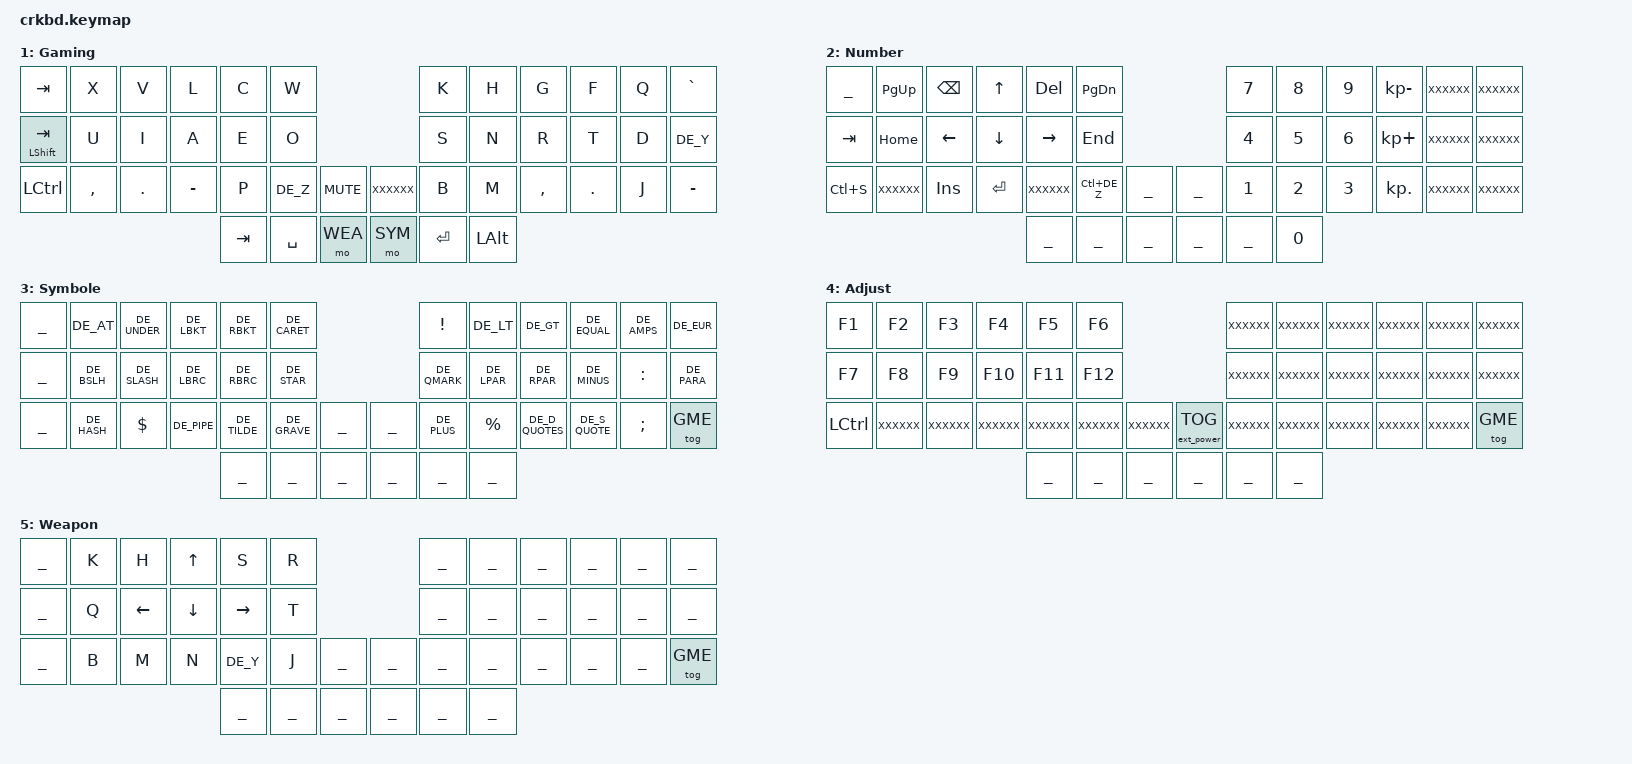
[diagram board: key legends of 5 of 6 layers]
 /*
 * Copyright (c) 2020 The ZMK Contributors
 *
 * SPDX-License-Identifier: MIT
 * NEO 2
 */


#include <behaviors.dtsi>
#include <dt-bindings/zmk/keys.h>
#include <dt-bindings/zmk/bt.h>
#include <dt-bindings/zmk/modifiers.h>
#include <dt-bindings/zmk/ext_power.h>
#include "define_keys.dtsi"
#include "taps.keymap"

#define WIN 0
#define GME 1
#define NUM 2
#define SYM 3
#define ADJ 4
#define WEA 5 


/ {

   // Activate ADJUST layer by pressing raise and lower
    conditional_layers {
        compatible = "zmk,conditional-layers";
        adjust_layer {
            if-layers = <SYM NUM>;
            then-layer = <ADJ>;
        };
    };

    keymap {
        compatible = "zmk,keymap";
        win_layer {
            label = "Windows";
            bindings = < RC(LA(R))
// ╭────────────────┬────────────────┬────────────────┬────────────────┬────────────────┬────────────────╮                                   ╭────────────────┬────────────────┬────────────────┬────────────────┬────────────────┬────────────────╮
        &kp ESC           &kp X            &kp V          &bhm F2 C       &bhm RC(D) C     &bhm RC(U) W                                            &kp K            &kp H            &kp G            &kp F            &kp Q           &kp DE_SS
// ├────────────────┼────────────────┼────────────────┼────────────────┼────────────────┼────────────────┤                                   ├────────────────┼────────────────┼────────────────┼────────────────┼────────────────┼────────────────┤
     &mt LSHIFT TAB  &bhm RC(LA(P)) U &bhm RC(LA(R)) I    &bhm F12 A      &bhm LS(F5) E     &bhm F5 O                                              &kp S            &kp N            &kp R            &kp T            &kp D           &kp DE_Y
// ├────────────────┼────────────────┼────────────────┼────────────────┼────────────────┼────────────────┤                                   ├────────────────┼────────────────┼────────────────┼────────────────┼────────────────┤────────────────┤
        &kp LCTRL       &kp DE_UE        &kp DE_OE        &kp DE_AE          &kp P           &kp DE_Z                                              &kp B            &kp M           &kp COMMA        &kp DOT           &kp J         &kp DE_MINUS
// ╰────────────────┴────────────────┴────────────────┴────────────────┼────────────────┼────────────────┤────────────────╮ ╭────────────────┼────────────────┼────────────────┼────────────────┴────────────────┴────────────────┴────────────────╯
                                                                         &mt LALT LGUI      &kp SPACE        &mo NUM             &mo SYM      &mt RSHIFT RET      &kp RALT       
//                                                                     ╰────────────────┴────────────────┴────────────────╯ ╰────────────────┴────────────────┴────────────────╯
            >;
            sensor-bindings = <&inc_dec_kp C_VOL_UP C_VOL_DN &inc_dec_kp PG_UP PG_DN>;
        };
// -------------------------------------------------------------------------------------------------------------------------------------------------------------------------------------------------------------------------------------------------
        gme_layer {
            label = "Gaming";
            bindings = <
// ╭────────────────┬────────────────┬────────────────┬────────────────┬────────────────┬────────────────╮                                   ╭────────────────┬────────────────┬────────────────┬────────────────┬────────────────┬────────────────╮
         &kp TAB          &kp X            &kp V             &kp L           &kp C            &kp W                                                &kp K            &kp H            &kp G             &kp F            &kp Q          &kp GRAVE
// ├────────────────┼────────────────┼────────────────┼────────────────┼────────────────┼────────────────┤                                   ├────────────────┼────────────────┼────────────────┼────────────────┼────────────────┼────────────────┤
     &mt LSHIFT TAB       &kp U            &kp I             &kp A           &kp E            &kp O                                                &kp S            &kp N            &kp R             &kp T            &kp D          &kp DE_Y
// ├────────────────┼────────────────┼────────────────┼────────────────┼────────────────┼────────────────┤────────────────╮ ╭────────────────┼────────────────┼────────────────┼────────────────┼────────────────┼────────────────┼────────────────┤
       &kp LCTRL        &kp COMMA         &kp DOT          &kp MINUS         &kp P           &kp DE_Z        &kp C_MUTE           XXXXXX           &kp B            &kp M           &kp COMMA         &kp DOT           &kp J          &kp MINUS
// ╰────────────────┴────────────────┴────────────────┴────────────────┼────────────────┼────────────────┤────────────────┤ ├────────────────┼────────────────┼────────────────┼────────────────┴────────────────┴────────────────┴────────────────╯
                                                                            &kp TAB          &kp SPACE         &mo WEA            &mo SYM          &kp RET         &kp LALT
//                                                                     ╰────────────────┴────────────────┴────────────────╯ ╰────────────────┴────────────────┴────────────────╯
            >;
            sensor-bindings = <&inc_dec_kp C_VOL_UP C_VOL_DN &inc_dec_kp PG_UP PG_DN>;
        };
// -------------------------------------------------------------------------------------------------------------------------------------------------------------------------------------------------------------------------------------------------
        num_layer {
            label = "Number";
            bindings = <

// ╭────────────────┬────────────────┬────────────────┬────────────────┬────────────────┬────────────────╮                                   ╭────────────────┬────────────────┬────────────────┬────────────────┬────────────────┬────────────────╮
         ______         &kp PAGE_UP       &kp BSPC           &kp UP          &kp DEL       &kp PAGE_DOWN                                          &kp N7            &kp N8           &kp N9        &kp KP_MINUS        XXXXXX           XXXXXX
// ├────────────────┼────────────────┼────────────────┼────────────────┼────────────────┼────────────────┤                                   ├────────────────┼────────────────┼────────────────┼────────────────┼────────────────┼────────────────┤
         &kp TAB         &kp HOME         &kp LEFT         &kp DOWN         &kp RIGHT        &kp END                                              &kp N4            &kp N5           &kp N6        &kp KP_PLUS         XXXXXX           XXXXXX
// ├────────────────┼────────────────┼────────────────┼────────────────┼────────────────┼────────────────┤────────────────╮ ╭────────────────┼────────────────┼────────────────┼────────────────┼────────────────┼────────────────┼────────────────┤
         &kp LC(S)        XXXXXX          &kp INS          &kp RET           XXXXXX         &kp LC(DE_Z)       ______             ______          &kp N1            &kp N2           &kp N3         &kp KP_DOT         XXXXXX           XXXXXX
// ╰────────────────┴────────────────┴────────────────┴────────────────┼────────────────┼────────────────┤────────────────┤ ├────────────────┼────────────────┼────────────────┼────────────────┴────────────────┴────────────────┴────────────────╯
                                                                             ______           ______           ______             ______           ______           &kp N0
//                                                                     ╰────────────────┴────────────────┴────────────────╯ ╰────────────────┴────────────────┴────────────────╯
            >;
            sensor-bindings = <&inc_dec_kp C_VOL_UP C_VOL_DN &inc_dec_kp PG_UP PG_DN>;
        };
// -------------------------------------------------------------------------------------------------------------------------------------------------------------------------------------------------------------------------------------------------
        sym_layer {
            label = "Symbole";
            bindings = <
// ╭────────────────┬────────────────┬────────────────┬────────────────┬────────────────┬────────────────╮                                   ╭────────────────┬────────────────┬────────────────┬────────────────┬────────────────┬────────────────╮
         ______          &kp DE_AT       &kp DE_UNDER     &kp DE_LBKT      &kp DE_RBKT     &kp DE_CARET                                            &kp EXCL        &kp DE_LT        &kp DE_GT       &kp DE_EQUAL     &kp DE_AMPS      &kp DE_EUR
// ├────────────────┼────────────────┼────────────────┼────────────────┼────────────────┼────────────────┤                                   ├────────────────┼────────────────┼────────────────┼────────────────┼────────────────┼────────────────┤
         ______         &kp DE_BSLH     &kp DE_SLASH      &kp DE_LBRC      &kp DE_RBRC     &kp DE_STAR                                          &kp DE_QMARK      &kp DE_LPAR      &kp DE_RPAR      &kp DE_MINUS     &kp COLON        &kp DE_PARA
// ├────────────────┼────────────────┼────────────────┼────────────────┼────────────────┼────────────────┤────────────────╮ ╭────────────────┼────────────────┼────────────────┼────────────────┼────────────────┼────────────────┼────────────────┤
         ______         &kp DE_HASH      &kp DOLLAR       &kp DE_PIPE     &kp DE_TILDE     &kp DE_GRAVE        ______            ______         &kp DE_PLUS       &kp PERCENT    &kp DE_D_QUOTES  &kp DE_S_QUOTE     &kp SEMI          &tog GME
// ╰────────────────┴────────────────┴────────────────┴────────────────┼────────────────┼────────────────┤────────────────┤ ├────────────────┼────────────────┼────────────────┼────────────────┴────────────────┴────────────────┴────────────────╯
                                                                             ______           ______           ______            ______            ______           ______
//                                                                     ╰────────────────┴────────────────┴────────────────╯ ╰────────────────┴────────────────┴────────────────╯
            >;
            sensor-bindings = <&inc_dec_cp C_VOL_UP C_VOL_DN &inc_dec_kp PG_UP PG_DN>;
        };
// -------------------------------------------------------------------------------------------------------------------------------------------------------------------------------------------------------------------------------------------------
        adj_layer {
            label = "Adjust";
            bindings = <
// ╭────────────────┬────────────────┬────────────────┬────────────────┬────────────────┬────────────────╮                                   ╭────────────────┬────────────────┬────────────────┬────────────────┬────────────────┬────────────────╮
         &kp F1           &kp F2           &kp F3          &kp F4           &kp F5           &kp F6                                                XXXXXX           XXXXXX           XXXXXX           XXXXXX           XXXXXX           XXXXXX
// ├────────────────┼────────────────┼────────────────┼────────────────┼────────────────┼────────────────┤                                   ├────────────────┼────────────────┼────────────────┼────────────────┼────────────────┼────────────────┤
         &kp F7           &kp F8           &kp F9          &kp F10          &kp F11          &kp F12                                                XXXXXX           XXXXXX           XXXXXX           XXXXXX           XXXXXX           XXXXXX
// ├────────────────┼────────────────┼────────────────┼────────────────┼────────────────┼────────────────┤────────────────╮ ╭────────────────┼────────────────┼────────────────┼────────────────┼────────────────┼────────────────┼────────────────┤
        &kp LCTRL         XXXXXX           XXXXXX          XXXXXX           XXXXXX           XXXXXX            XXXXXX        &ext_power EP_TOG     XXXXXX           XXXXXX           XXXXXX           XXXXXX           XXXXXX           &tog GME
// ╰────────────────┴────────────────┴────────────────┴────────────────┼────────────────┼────────────────┤────────────────┤ ├────────────────┼────────────────┼────────────────┼────────────────┴────────────────┴────────────────┴────────────────╯
                                                                            ______           ______            ______             ______           ______           ______
//                                                                     ╰────────────────┴────────────────┴────────────────╯ ╰────────────────┴────────────────┴────────────────╯
            >;
            sensor-bindings = <&inc_dec_kp C_VOL_UP C_VOL_DN &inc_dec_kp PG_UP PG_DN>;
        };
// -------------------------------------------------------------------------------------------------------------------------------------------------------------------------------------------------------------------------------------------------
        wea_layer {
            label = "Weapon";
            bindings = <
// ╭────────────────┬────────────────┬────────────────┬────────────────┬────────────────┬────────────────╮                                   ╭────────────────┬────────────────┬────────────────┬────────────────┬────────────────┬────────────────╮
         ______           &kp K            &kp H            &kp UP            &kp S           &kp R                                                ______           ______           ______           ______           ______           ______
// ├────────────────┼────────────────┼────────────────┼────────────────┼────────────────┼────────────────┤                                   ├────────────────┼────────────────┼────────────────┼────────────────┼────────────────┼────────────────┤
         ______           &kp Q            &kp LEFT        &kp DOWN        &kp RIGHT          &kp T                                                ______           ______           ______           ______           ______           ______
// ├────────────────┼────────────────┼────────────────┼────────────────┼────────────────┼────────────────┤────────────────╮ ╭────────────────┼────────────────┼────────────────┼────────────────┼────────────────┼────────────────┼────────────────┤
         ______           &kp B            &kp M            &kp N           &kp DE_Y          &kp J            ______             ______           ______           ______           ______           ______           ______           &tog GME
// ╰────────────────┴────────────────┴────────────────┴────────────────┼────────────────┼────────────────┤────────────────┤ ├────────────────┼────────────────┼────────────────┼────────────────┴────────────────┴────────────────┴────────────────╯
                                                                             ______           ______           ______             ______           ______           ______
//                                                                     ╰────────────────┴────────────────┴────────────────╯ ╰────────────────┴────────────────┴────────────────╯
            >;
            sensor-bindings = <&inc_dec_kp C_VOL_UP C_VOL_DN &inc_dec_kp PG_UP PG_DN>;
        };
     };
};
